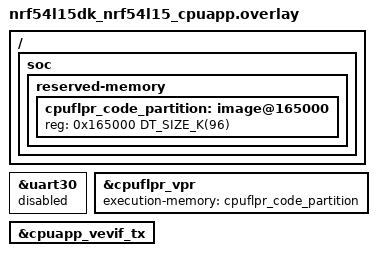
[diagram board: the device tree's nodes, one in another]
/*
 * Copyright (c) 2024 Nordic Semiconductor
 * SPDX-License-Identifier: Apache-2.0
 */

/ {
	soc {
		reserved-memory {
			#address-cells = <1>;
			#size-cells = <1>;
			cpuflpr_code_partition: image@165000 {
				/* FLPR core code partition */
				reg = <0x165000 DT_SIZE_K(96)>;
			};
		};
	};
};

&uart30 {
	status = "reserved";
};

&cpuflpr_vpr {
	execution-memory = <&cpuflpr_code_partition>;
};

&cpuapp_vevif_tx {
	status = "okay";
};
